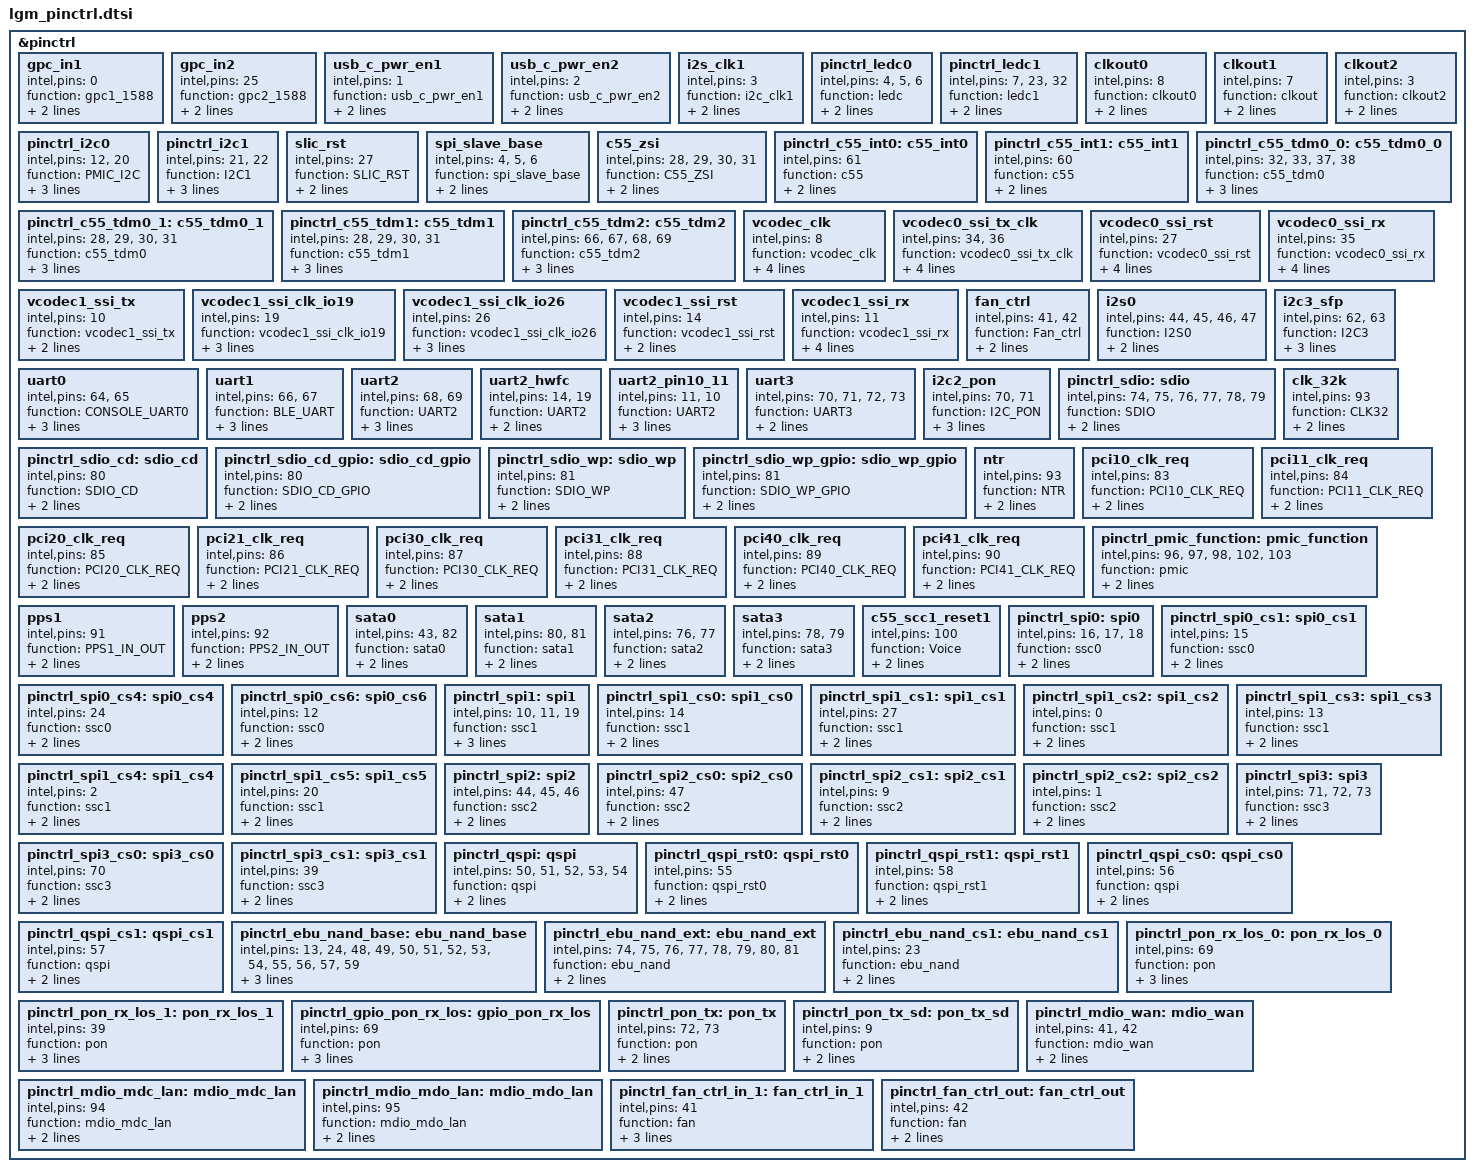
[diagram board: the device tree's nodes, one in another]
// SPDX-License-Identifier: GPL-2.0
/*
 * Copyright (C) 2020-2022 MaxLinear, Inc.
 * Copyright (C) 2018-2020 Intel Corporation.
 *
 * This program is free software; you can redistribute it and/or modify it
 * under the terms of the GNU General Public License, as published by the Free
 * Software Foundation; either version 2 of the License, or (at your option)
 * any later version.
 *
 * This program is distributed in the hope that it will be useful, but WITHOUT
 * ANY WARRANTY; without even the implied warranty of MERCHANTABILITY or
 * FITNESS FOR A PARTICULAR PURPOSE.
 * See the GNU General Public License for more details.
 *
 * You should have received a copy of the GNU General Public License along
 * with this program; if not, see <http://www.gnu.org/licenses/>.
 */

/* topmux format: <offset  mask  value> */
&pinctrl {
	gpc_in1:gpc_in1 {
		intel,pins = <0>; /* GPC1_1588 */
		function = "gpc1_1588";
		pinmux = <1>;
		groups = "gpc1_1588";
	};

	gpc_in2:gpc_in2 {
		intel,pins = <25>; /* GPC2_1588 */
		function = "gpc2_1588";
		pinmux = <3>;
		groups = "gpc2_1588";
	};

	usb_c_pwr_en1:usb_c_pwr_en1 {
		intel,pins = <1>;
		function = "usb_c_pwr_en1";
		pinmux = <1>;
		groups = "usb_c_pwr_en1";
	};

	usb_c_pwr_en2:usb_c_pwr_en2 {
		intel,pins = <2>;
		function = "usb_c_pwr_en2";
		pinmux = <1>;
		groups = "usb_c_pwr_en2";
	};

	i2s_clk1:i2s_clk1 {
		intel,pins = <3>;
		function = "i2c_clk1";
		pinmux = <2>;
		groups = "i2c_clk1";
	};

	pinctrl_ledc0:pinctrl_ledc0 {
		intel,pins =  <4>, /* LED_SH */
			<5>, /* LED_ST */
			<6>; /* LED_D */
		function = "ledc";
		pinmux = <1>;
		groups = "ledc";
	};

	pinctrl_ledc1:pinctrl_ledc1 {
		intel,pins =  <7>, /* LED_SH */
			<23>, /* LED_ST */
			<32>; /* LED_D */
		function = "ledc1";
		pinmux = <1>,
			 <2>,
			 <1>;
		groups = "ledc1";
	};

	clkout0:clkout0 {
		intel,pins = <8>; /* clkout0 */
		function = "clkout0";
		pinmux = <2>;
		groups = "clkout0";
	};

	clkout1:clkout1 {
		intel,pins = <7>; /* CLKOUT1 */
		function = "clkout";
		pinmux = <2>;
		groups = "clkout";
	};

	clkout2:clkout2 {
		intel,pins = <3>; /* clkout2 */
		function = "clkout2";
		pinmux = <1>;
		groups = "clkout2";
	};

	pinctrl_i2c0:pinctrl_i2c0 {
		intel,pins =  <12>, /* I2C_SDA */
			<20>; /* I2C_SCL */
		function = "PMIC_I2C";
		pinmux = <2>;
		groups = "PMIC_I2C";
		drive-open-drain = <1>;
	};

	pinctrl_i2c1:pinctrl_i2c1 {
		intel,pins =  <21>, /* I2C1_SCL */
			<22>; /* I2C1_SDA */
		function = "I2C1";
		pinmux = <2>;
		groups = "I2C1";
		drive-open-drain = <1>;
	};

	slic_rst:slic_rst {
		intel,pins = <27>; /* SLIC_RST */
		function = "SLIC_RST";
		pinmux = <1>;
		groups = "SLIC_RST";
	};

	spi_slave_base:spi_slave_base {
		intel,pins =  <4>, /* SPI_CLK */
			<5>, /* SPI_IN */
			<6>; /* SPI_OUT */
		function = "spi_slave_base";
		pinmux = <3>;
		groups = "spi_slave_base";
	};

	c55_zsi:c55_zsi {
		intel,pins =  <28>, /* C55_ZSI_FSC */
			<29>, /* C55_ZSI_M2S */
			<30>, /* C55_ZSI_S2M */
			<31>; /* C55_ZSI_DCL */
		function = "C55_ZSI";
		pinmux = <1>;
		groups = "C55_ZSI";
	};

	pinctrl_c55_int0: c55_int0 {
		intel,pins = <61>; /* C55_INT0 */
		function = "c55";
		pinmux = <2>;
		groups = "c55_int0";
	};

	pinctrl_c55_int1: c55_int1 {
		intel,pins = <60>; /* C55_INT1 */
		function = "c55";
		pinmux = <2>;
		groups = "c55_int1";
	};

	pinctrl_c55_tdm0_0: c55_tdm0_0 {
		intel,pins =  <32>, /* C55_TDM_FSC */
			<33>, /* C55_TDM_DO */
			<37>, /* C55_TDM_DI */
			<38>; /* C55_TDM_DCL */
		function = "c55_tdm0";
		pinmux = <2>;
		groups = "c55_tdm0_0";
		topmux = <0xE0 0x84 0x4>;
	};

	pinctrl_c55_tdm0_1: c55_tdm0_1 {
		intel,pins =  <28>, /* C55_TDM_FSC */
			<29>, /* C55_TDM_DO  */
			<30>, /* C55_TDM_DI  */
			<31>; /* C55_TDM_DCL */
		function = "c55_tdm0";
		pinmux = <2>;
		groups = "c55_tdm0_1";
		topmux = <0xE0 0xC8 0xC0>;
	};

	pinctrl_c55_tdm1: c55_tdm1 {
		intel,pins =  <28>, /* C55_TDM_FSC */
			<29>, /* C55_TDM_DO  */
			<30>, /* C55_TDM_DI  */
			<31>; /* C55_TDM_DCL */
		function = "c55_tdm1";
		pinmux = <2>;
		groups = "c55_tdm1";
		topmux = <0xE0 0x48 0x48>;
	};

	pinctrl_c55_tdm2: c55_tdm2 {
		intel,pins =  <66>, /* C55_TDM_FSC */
			<67>, /* C55_TDM_DO  */
			<68>, /* C55_TDM_DI  */
			<69>; /* C55_TDM_DCL */
		function = "c55_tdm2";
		pinmux = <2>;
		groups = "c55_tdm2";
		topmux = <0xE0 0x10 0x10>;
	};

	vcodec_clk:vcodec_clk {
		intel,pins = <8>; /* CLKOUT0 */
		function = "vcodec_clk";
		pinmux = <2>;
		groups = "vcodec_clk";
		bias-pull-down = <0>;
		bias-pull-up = <0>;
	};

	vcodec0_ssi_tx_clk:vcodec0_ssi_tx_clk {
		intel,pins =  <34>, /* SSI0_TX */
			<36>; /* SSI0_CLK */
		function = "vcodec0_ssi_tx_clk";
		pinmux = <1>;
		groups = "vcodec0_ssi_tx_clk";
		bias-pull-down = <1>;
		bias-pull-up = <0>;
	};

	vcodec0_ssi_rst:vcodec0_ssi_rst {
		intel,pins = <27>; /* SLIC_RST0 */
		function = "vcodec0_ssi_rst";
		pinmux = <1>;
		groups = "vcodec0_ssi_rst";
		bias-pull-down = <0>;
		bias-pull-up = <0>;
	};

	vcodec0_ssi_rx:vcodec0_ssi_rx {
		intel,pins = <35>; /* SSI0_RX */
		function = "vcodec0_ssi_rx";
		pinmux = <1>;
		groups = "vcodec0_ssi_rx";
		bias-pull-down = <0>;
		bias-pull-up = <1>;
	};

	vcodec1_ssi_tx:vcodec1_ssi_tx {
		intel,pins = <10>; /* SSI1_TX */
		function = "vcodec1_ssi_tx";
		pinmux = <2>;
		groups = "vcodec1_ssi_tx";
	};

	vcodec1_ssi_clk_io19:vcodec1_ssi_clk_io19 {
		intel,pins = <19>; /* SSI1_CLK */
		function = "vcodec1_ssi_clk_io19";
		pinmux = <2>;
		groups = "vcodec1_ssi_clk_io19";
		topmux = <0xE4 0x2000 0x2000>;
	};

	vcodec1_ssi_clk_io26:vcodec1_ssi_clk_io26 {
		intel,pins = <26>; /* SSI1_CLK */
		function = "vcodec1_ssi_clk_io26";
		pinmux = <3>;
		groups = "vcodec1_ssi_clk_io26";
		topmux = <0xE4 0x2000 0>;
	};

	vcodec1_ssi_rst:vcodec1_ssi_rst {
		intel,pins = <14>; /* SLIC_RST1 */
		function = "vcodec1_ssi_rst";
		pinmux = <2>;
		groups = "vcodec1_ssi_rst";
	};

	vcodec1_ssi_rx:vcodec1_ssi_rx {
		intel,pins = <11>; /* SSI1_RX */
		function = "vcodec1_ssi_rx";
		pinmux = <2>;
		groups = "vcodec1_ssi_rx";
		bias-pull-down = <0>;
		bias-pull-up = <1>;
	};

	fan_ctrl:fan_ctrl {
		intel,pins =  <41>, /* FAN_CTRL_IN */
			<42>; /* FAN_CTRL_OUT */
		function = "Fan_ctrl";
		pinmux = <3>;
		groups = "Fan_ctrl";
	};

	i2s0:i2s0 {
		intel,pins =  <44>, /* I2S_CLK0 */
			<45>, /* I2SWA0 */
			<46>, /* I2S_RX0 */
			<47>; /* I2S_TX0 */
		function = "I2S0";
		pinmux = <1>;
		groups = "I2S0";
	};

	i2c3_sfp:i2c3_sfp {
		intel,pins =  <62>, /* I2C3_SCL */
			<63>; /* I2C3_SDA */
		function = "I2C3";
		pinmux = <1>;
		groups = "I2C3";
		drive-open-drain = <1>;
	};

	uart0:uart0 {
		intel,pins =  <64>, /* UART_RX0 */
			<65>; /* UART_TX0 */
		function = "CONSOLE_UART0";
		pinmux = <1>;
		groups = "CONSOLE_UART0";
		topmux = <0xE8 0x3 0>;
	};

	uart1:uart1 {
		intel,pins =  <66>, /* UART_RX1 */
			<67>; /* UART_TX1 */
		function = "BLE_UART";
		pinmux = <1>;
		groups = "BLE_UART";
		topmux = <0xE8 0xC 0>;
	};

	uart2:uart2 {
		intel,pins =  <68>, /* UART_RX2 */
			<69>; /* UART_TX2 */
		function = "UART2";
		pinmux = <1>;
		groups = "UART2";
		topmux = <0xE4 0x200 0>,
			 <0xE8 0x30 0>;
	};

	uart2_hwfc:uart2_hwfc {
		intel,pins = <14>,  /* UART2_RTS */
			     <19>;  /* UART2_CTS */
		function = "UART2";
		pinmux = <3>;
		groups = "UART2_HWFC";
	};

	uart2_pin10_11:uart2_pin10_11 {
		intel,pins =  <11>, /* UART_RX2 */
			<10>; /* UART_TX2 */
		function = "UART2";
		pinmux = <3>;
		groups = "UART2";
		topmux = <0xE4 0x200 0x200>,
			 <0xE0 0x20 0>;
	};

	uart3:uart3 {
		intel,pins =  <70>, /* UART_RX3 */
			<71>, /* UART_TX3 */
			<72>, /* UART3_RTS */
			<73>; /* UART3_CTS */
		function = "UART3";
		pinmux = <2>;
		groups = "UART3";
	};

	i2c2_pon:i2c2_pon {
		intel,pins =  <70>, /* I2C2_SDA */
			<71>; /* I2C2_SCL */
		function = "I2C_PON";
		pinmux = <1>;
		groups = "I2C_PON";
		drive-open-drain = <1>;
	};

	pinctrl_sdio:sdio {
		intel,pins =  <74>, /* SDIO_CLK */
			<75>, /* SDIO_CMD */
			<76>, /* SDIO_D2 */
			<77>, /* SDIO_D3 */
			<78>, /* SDIO_D1 */
			<79>; /* SDIO_D0 */
		function = "SDIO";
		pinmux = <2>;
		groups = "SDIO";
	};

	pinctrl_sdio_cd: sdio_cd {
		intel,pins = <80>;	/* SDIO_CD */
		function = "SDIO_CD";
		pinmux = <2>;
		groups = "SDIO_CD";
	};

	pinctrl_sdio_cd_gpio: sdio_cd_gpio {
		intel,pins = <80>;	/* SDIO_CD */
		function = "SDIO_CD_GPIO";
		pinmux = <0>;
		groups = "SDIO_CD_GPIO";
	};

	pinctrl_sdio_wp: sdio_wp {
		intel,pins = <81>;	/* SDIO_WP */
		function = "SDIO_WP";
		pinmux = <2>;
		groups = "SDIO_WP";
	};

	pinctrl_sdio_wp_gpio: sdio_wp_gpio {
		intel,pins = <81>;	/* SDIO_WP */
		function = "SDIO_WP_GPIO";
		pinmux = <0>;
		groups = "SDIO_WP_GPIO";
	};

	clk_32k:clk_32k {
		intel,pins = <93>; /* CLK32 */
		function = "CLK32";
		pinmux = <1>;
		groups = "CLK32";
	};

	ntr:ntr {
		intel,pins = <93>; /* NTR */
		function = "NTR";
		pinmux = <2>;
		groups = "NTR";
	};

	pci10_clk_req:pci10_clk_req {
		intel,pins = <83>; /* PCI10_CLK_REQ */
		function = "PCI10_CLK_REQ";
		pinmux = <2>;
		groups = "PCI10_CLK_REQ";
	};

	pci11_clk_req:pci11_clk_req {
		intel,pins = <84>; /* PCI11_CLK_REQ */
		function = "PCI11_CLK_REQ";
		pinmux = <2>;
		groups = "PCI11_CLK_REQ";
	};

	pci20_clk_req:pci20_clk_req {
		intel,pins = <85>; /* PCI20_CLK_REQ */
		function = "PCI20_CLK_REQ";
		pinmux = <2>;
		groups = "PCI20_CLK_REQ";
	};

	pci21_clk_req:pci21_clk_req {
		intel,pins = <86>; /* PCI21_CLK_REQ */
		function = "PCI21_CLK_REQ";
		pinmux = <2>;
		groups = "PCI21_CLK_REQ";
	};

	pci30_clk_req:pci30_clk_req {
		intel,pins = <87>; /* PCI30_CLK_REQ */
		function = "PCI30_CLK_REQ";
		pinmux = <2>;
		groups = "PCI30_CLK_REQ";
	};

	pci31_clk_req:pci31_clk_req {
		intel,pins = <88>; /* PCI31_CLK_REQ */
		function = "PCI31_CLK_REQ";
		pinmux = <2>;
		groups = "PCI31_CLK_REQ";
	};

	pci40_clk_req:pci40_clk_req {
		intel,pins = <89>; /* PCI40_CLK_REQ */
		function = "PCI40_CLK_REQ";
		pinmux = <2>;
		groups = "PCI40_CLK_REQ";
	};

	pci41_clk_req:pci41_clk_req {
		intel,pins = <90>; /* PCI41_CLK_REQ */
		function = "PCI41_CLK_REQ";
		pinmux = <2>;
		groups = "PCI41_CLK_REQ";
	};

	pinctrl_pmic_function:pmic_function {
		intel,pins =  <96>, /* PMIC_GPIO0 */
			<97>, /* PMIC_GPIO1 */
			<98>, /* PMIC_GPIO2 */
			<102>, /* PMIC_GPIO3 */
			<103>; /* PMIC_GPIO4 */
		function = "pmic";
		pinmux = <1>;
		groups = "pmic_function";
	};

	pps1:pps1 {
		intel,pins = <91>; /* PPS1_IN_OUT */
		function = "PPS1_IN_OUT";
		pinmux = <1>;
		groups = "PPS1_IN_OUT";
	};

	pps2:pps2 {
		intel,pins = <92>; /* PPS2_IN_OUT */
		function = "PPS2_IN_OUT";
		pinmux = <1>;
		groups = "PPS2_IN_OUT";
	};

	sata0:sata0 {
		intel,pins =  <43>, /* SATA0_MP_SWITCH */
			<82>; /* SATA0_CP_DETECT */
		function = "sata0";
		pinmux = <2>;
		groups = "sata0";
	};

	sata1:sata1 {
		intel,pins =  <80>, /* SATA1_MP_SWITCH */
			<81>; /* SATA1_CP_DETECT */
		function = "sata1";
		pinmux = <3>;
		groups = "sata1";
	};

	sata2:sata2 {
		intel,pins =  <76>, /* SATA2_MP_SWITCH */
			<77>; /* SATA2_CP_DETECT */
		function = "sata2";
		pinmux = <3>;
		groups = "sata2";
	};

	sata3:sata3 {
		intel,pins =  <78>, /* SATA3_MP_SWITCH */
			<79>; /* SATA3_CP_DETECT */
		function = "sata3";
		pinmux = <3>;
		groups = "sata3";
	};

	c55_scc1_reset1:c55_scc1_reset1 {
		intel,pins = <100>; /* C55_RESET */
		function = "Voice";
		pinmux = <1>;
		groups = "Voice";
	};

	pinctrl_spi0: spi0 {
		intel,pins =  <16>,	/* SPI0_DIN */
			<17>,	/* SPI0_DOUT */
			<18>;	/* SPI0_CLK */
		function = "ssc0";
		pinmux = <1>;
		groups = "spi0";
	};

	pinctrl_spi0_cs1: spi0_cs1 {
		intel,pins = <15>;	/* SPI0_CS1 */
		function = "ssc0";
		pinmux = <1>;
		groups = "spi0_cs1";
	};

	pinctrl_spi0_cs4: spi0_cs4 {
		intel,pins = <24>;	/* SPI0_CS4 */
		function = "ssc0";
		pinmux = <3>;
		groups = "spi0_cs4";
	};

	pinctrl_spi0_cs6: spi0_cs6 {
		intel,pins = <12>;	/* SPI0_CS6 */
		function = "ssc0";
		pinmux = <3>;
		groups = "spi0_cs6";
	};

	pinctrl_spi1: spi1 {
		intel,pins =  <10>,	/* SPI1_TX */
			<11>,	/* SPI1_RX */
			<19>;	/* SPI1_CLK */
		function = "ssc1";
		pinmux = <1>;
		groups = "spi1";
		topmux = <0xE0 0x1 0>;
	};

	pinctrl_spi1_cs0: spi1_cs0 {
		intel,pins = <14>;	/* SPI1_CS0 */
		function = "ssc1";
		pinmux = <1>;
		groups = "spi1_cs0";
	};

	pinctrl_spi1_cs1: spi1_cs1 {
		intel,pins = <27>;	/* SPI1_CS1 */
		function = "ssc1";
		pinmux = <2>;
		groups = "spi1_cs1";
	};

	pinctrl_spi1_cs2: spi1_cs2 {
		intel,pins = <0>;	/* SPI1_CS2_N */
		function = "ssc1";
		pinmux = <3>;
		groups = "spi1_cs2_n";
	};

	pinctrl_spi1_cs3: spi1_cs3 {
		intel,pins = <13>;	/* SPI1_CS3_N */
		function = "ssc1";
		pinmux = <3>;
		groups = "spi1_cs3_n";
	};

	pinctrl_spi1_cs4: spi1_cs4 {
		intel,pins = <2>;	/* SPI1_CS4_N */
		function = "ssc1";
		pinmux = <3>;
		groups = "spi1_cs4_n";
	};

	pinctrl_spi1_cs5: spi1_cs5 {
		intel,pins = <20>;	/* SPI1_CS5 */
		function = "ssc1";
		pinmux = <3>;
		groups = "spi1_cs5";
	};

	pinctrl_spi2: spi2 {
		intel,pins =  <44>,	/* SPI2_CLK */
			<45>,	/* SPI2_TX */
			<46>;	/* SPI2_RX */
		function = "ssc2";
		pinmux = <2>;
		groups = "spi2.1";
	};

	pinctrl_spi2_cs0: spi2_cs0 {
		intel,pins = <47>;	/* SPI2_CS0 */
		function = "ssc2";
		pinmux = <2>;
		groups = "spi2_cs0";
	};

	pinctrl_spi2_cs1: spi2_cs1 {
		intel,pins = <9>;	/* SPI2_CS1_N */
		function = "ssc2";
		pinmux = <1>;
		groups = "spi2_cs1_n";
	};

	pinctrl_spi2_cs2: spi2_cs2 {
		intel,pins = <1>;	/* SPI2_CS2_N */
		function = "ssc2";
		pinmux = <3>;
		groups = "spi2_cs2_n";
	};

	pinctrl_spi3: spi3 {
		intel,pins =  <71>,	/* SPI3_TX */
			<72>,	/* SPI3_RX */
			<73>;	/* SPI3_CLK */
		function = "ssc3";
		pinmux = <3>;
		groups = "spi3";
	};

	pinctrl_spi3_cs0: spi3_cs0 {
		intel,pins = <70>;	/* SPI3_CS0 */
		function = "ssc3";
		pinmux = <3>;
		groups = "spi3_cs0";
	};

	pinctrl_spi3_cs1: spi3_cs1 {
		intel,pins = <39>;	/* SPI3_CS1 */
		function = "ssc3";
		pinmux = <2>;
		groups = "spi3_cs1";
	};

	pinctrl_qspi:qspi {
		intel,pins =  <50>, /* QSPI_D1 */
			<51>, /* QSPI_D0 */
			<52>, /* QSPI_D2 */
			<53>, /* QSPI_D3 */
			<54>; /* QSPI_CLK */
		function = "qspi";
		pinmux = <3>;
		groups = "qspi";
	};

	pinctrl_qspi_rst0:qspi_rst0 {
		intel,pins = <55>; /* QSPI_RST0 */
		function = "qspi_rst0";
		pinmux = <3>;
		groups = "qspi_rst0";
	};

	pinctrl_qspi_rst1:qspi_rst1 {
		intel,pins = <58>; /* QSPI_RST1 */
		function = "qspi_rst1";
		pinmux = <3>;
		groups = "qspi_rst1";
	};

	pinctrl_qspi_cs0: qspi_cs0 {
		intel,pins = <56>;  /* QSPI_CS0 */
		function = "qspi";
		pinmux = <3>;
		groups = "qspi_cs0";
	};

	pinctrl_qspi_cs1:qspi_cs1 {
		intel,pins = <57>; /* QSPI_CS1 */
		function = "qspi";
		pinmux = <3>;
		groups = "qspi_cs1";
	};

	pinctrl_ebu_nand_base:ebu_nand_base {
		intel,pins =  <13>, /* nand ale */
			<24>, /* nand cle */
			<48>, /* nand rdy */
			<49>, /* nand rd */
			<50>, /* nand d1 */
			<51>, /* nand d0 */
			<52>, /* nand d2 */
			<53>, /* nand d7 */
			<54>, /* nand d6 */
			<55>, /* nand d5 */
			<56>, /* nand d4 */
			<57>, /* nand d3 */
			<59>; /* nand wr */
		function = "ebu_nand_base";
		pinmux = <1>;
		groups = "ebu_nand_base";
	};

	pinctrl_ebu_nand_ext: ebu_nand_ext {
		intel,pins =  <74>,      /* nand d13 */
			<75>,   /* nand d12 */
			<76>,   /* nand d10 */
			<77>,   /* nand d11 */
			<78>,   /* nand d9 */
			<79>,   /* nand d8 */
			<80>,   /* nand d14 */
			<81>;   /* nand d15 */
		function = "ebu_nand";
		pinmux = <1>;
		groups = "ebu_nand_ext";
	};

	pinctrl_ebu_nand_cs1: ebu_nand_cs1 {
		intel,pins = <23>;      /* NAND_CS1 */
		function = "ebu_nand";
		pinmux = <1>;
		groups = "ebu_nand_cs1";
	};

	pinctrl_pon_rx_los_0: pon_rx_los_0 {
		intel,pins = <69>;	/* PON_RX_LOS */
		function = "pon";
		pinmux = <1>;
		groups = "pon_los_0";
		topmux = <0xE4 0x880 0x80>;
	};

	pinctrl_pon_rx_los_1: pon_rx_los_1 {
		intel,pins = <39>;	/* PON_RX_LOS */
		function = "pon";
		pinmux = <1>;
		groups = "pon_los_1";
		topmux = <0xE4 0x800 0x800>;
	};

	pinctrl_gpio_pon_rx_los: gpio_pon_rx_los {
		intel,pins = <69>;	/* GPIO_PON_RX_LOS */
		function = "pon";
		pinmux = <0>;
		groups = "gpio_pon_los";
		topmux = <0xE4 0x80 0>;
	};

	pinctrl_pon_tx: pon_tx {
		intel,pins =  <72>,	/* PON_TX_FAULT */
			<73>;	/* PON_TX_DISABLE */
		function = "pon";
		pinmux = <1>;
		groups = "pon_tx";
	};

	pinctrl_pon_tx_sd: pon_tx_sd {
		intel,pins = <9>;	/* PON_TX_SD */
		function = "pon";
		pinmux = <2>;
		groups = "pon_tx_sd";
	};

	pinctrl_mdio_wan: mdio_wan {
		intel,pins =  <41>,	/* MDIO_WANC */
			<42>;	/* MDIO_WAN */
		function = "mdio_wan";
		pinmux = <1>;
		groups = "mdio_wan";
		/*drive-open-drain = <1>;*/
	};

	pinctrl_mdio_mdc_lan: mdio_mdc_lan {
		intel,pins = <94>;	/* MDIO_LANC */
		function = "mdio_mdc_lan";
		pinmux = <1>;
		groups = "mdio_mdc_lan";
	};

	pinctrl_mdio_mdo_lan: mdio_mdo_lan {
		intel,pins = <95>;	/* MDIO_LAN */
		function = "mdio_mdo_lan";
		pinmux = <1>;
		groups = "mdio_mdo_lan";
		/*drive-open-drain = <1>;*/
	};

	pinctrl_fan_ctrl_in_1: fan_ctrl_in_1 {
		intel,pins = <41>;  /* FAN_CTRL_IN */
		function = "fan";
		pinmux = <3>;
		groups = "fan_ctrl_in_1";
		topmux = <0xE4 0x400 0x400>;
	};

	pinctrl_fan_ctrl_out: fan_ctrl_out {
		intel,pins = <42>;  /* FAN_CTRL_OUT */
		function = "fan";
		pinmux = <3>;
		groups = "fan_ctrl_out";
	};
};

